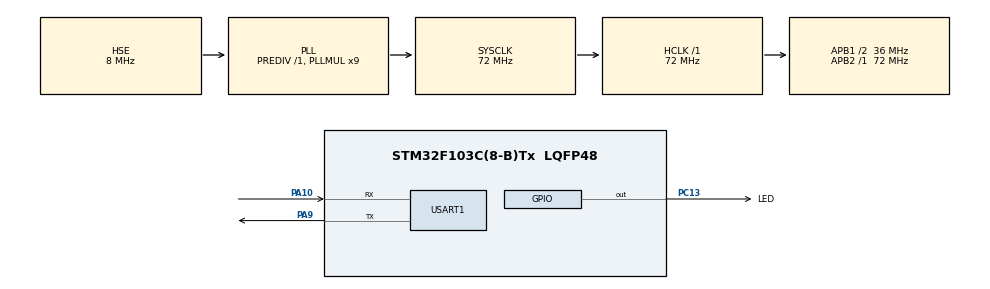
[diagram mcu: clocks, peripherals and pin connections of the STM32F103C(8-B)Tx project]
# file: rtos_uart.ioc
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FREERTOS.Tasks01=defaultTask,0,128,StartDefaultTask,Default,NULL
Mcu.Family=STM32F1
Mcu.Name=STM32F103C(8-B)Tx
Mcu.Package=LQFP48
NVIC.PriorityGroup=NVIC_PRIORITYGROUP_4
PA10.Mode=Asynchronous
PA10.Signal=USART1_RX
PA13.Mode=Serial_Wire
PA13.Signal=SYS_JTMS-SWDIO
PA14.Mode=Serial_Wire
PA14.Signal=SYS_JTCK-SWCLK
PA9.Mode=Asynchronous
PA9.Signal=USART1_TX
PC13-TAMPER-RTC.GPIO_Label=LED
PC13-TAMPER-RTC.Signal=GPIO_Output
PD0-OSC_IN.Mode=HSE-External-Oscillator
PD0-OSC_IN.Signal=RCC_OSC_IN
PD1-OSC_OUT.Mode=HSE-External-Oscillator
PD1-OSC_OUT.Signal=RCC_OSC_OUT
ProjectManager.HeapSize=0x200
ProjectManager.StackSize=0x400
ProjectManager.TargetToolchain=Makefile
RCC.AHBFreq_Value=72000000
RCC.APB1CLKDivider=RCC_HCLK_DIV2
RCC.APB1Freq_Value=36000000
RCC.APB1TimFreq_Value=72000000
RCC.APB2Freq_Value=72000000
RCC.APB2TimFreq_Value=72000000
RCC.HCLKFreq_Value=72000000
RCC.PLLMUL=RCC_PLL_MUL9
RCC.PLLSourceVirtual=RCC_PLLSOURCE_HSE
RCC.SYSCLKFreq_VALUE=72000000
RCC.SYSCLKSource=RCC_SYSCLKSOURCE_PLLCLK
RCC.USBFreq_Value=72000000
USART1.VirtualMode=VM_ASYNC
VP_FREERTOS_VS_ENABLE.Mode=Enabled
board=custom

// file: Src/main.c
/* USER CODE BEGIN Header */
/**
  ******************************************************************************
  * @file           : main.c
  * @brief          : Main program body
  ******************************************************************************
  * This notice applies to any and all portions of this file
  * that are not between comment pairs USER CODE BEGIN and
  * USER CODE END. Other portions of this file, whether
  * inserted by the user or by software development tools
  * are owned by their respective copyright owners.
  *
  * Copyright (c) 2019 STMicroelectronics International N.V.
  * All rights reserved.
  *
  * Redistribution and use in source and binary forms, with or without
  * modification, are permitted, provided that the following conditions are met:
  *
  * 1. Redistribution of source code must retain the above copyright notice,
  *    this list of conditions and the following disclaimer.
  * 2. Redistributions in binary form must reproduce the above copyright notice,
  *    this list of conditions and the following disclaimer in the documentation
  *    and/or other materials provided with the distribution.
  * 3. Neither the name of STMicroelectronics nor the names of other
  *    contributors to this software may be used to endorse or promote products
  *    derived from this software without specific written permission.
  * 4. This software, including modifications and/or derivative works of this
  *    software, must execute solely and exclusively on microcontroller or
  *    microprocessor devices manufactured by or for STMicroelectronics.
  * 5. Redistribution and use of this software other than as permitted under
  *    this license is void and will automatically terminate your rights under
  *    this license.
  *
  * THIS SOFTWARE IS PROVIDED BY STMICROELECTRONICS AND CONTRIBUTORS "AS IS"
  * AND ANY EXPRESS, IMPLIED OR STATUTORY WARRANTIES, INCLUDING, BUT NOT
  * LIMITED TO, THE IMPLIED WARRANTIES OF MERCHANTABILITY, FITNESS FOR A
  * PARTICULAR PURPOSE AND NON-INFRINGEMENT OF THIRD PARTY INTELLECTUAL PROPERTY
  * RIGHTS ARE DISCLAIMED TO THE FULLEST EXTENT PERMITTED BY LAW. IN NO EVENT
  * SHALL STMICROELECTRONICS OR CONTRIBUTORS BE LIABLE FOR ANY DIRECT, INDIRECT,
  * INCIDENTAL, SPECIAL, EXEMPLARY, OR CONSEQUENTIAL DAMAGES (INCLUDING, BUT NOT
  * LIMITED TO, PROCUREMENT OF SUBSTITUTE GOODS OR SERVICES; LOSS OF USE, DATA,
  * OR PROFITS; OR BUSINESS INTERRUPTION) HOWEVER CAUSED AND ON ANY THEORY OF
  * LIABILITY, WHETHER IN CONTRACT, STRICT LIABILITY, OR TORT (INCLUDING
  * NEGLIGENCE OR OTHERWISE) ARISING IN ANY WAY OUT OF THE USE OF THIS SOFTWARE,
  * EVEN IF ADVISED OF THE POSSIBILITY OF SUCH DAMAGE.
  *
  ******************************************************************************
  */
/* USER CODE END Header */

#include "main.h"
#include "cmsis_os.h"

UART_HandleTypeDef huart1;

osThreadId defaultTaskHandle;

void SystemClock_Config(void);
static void MX_GPIO_Init(void);
static void MX_USART1_UART_Init(void);
void StartDefaultTask(void const * argument);

/* USER CODE BEGIN 0 */
uint32_t mstrlen(const uint8_t* str, uint32_t maxsize) {
	uint32_t i = 0;
	for (i = 0; maxsize >= i && str[i] != '\0'; ++i);
	return i;
}

void LED_Task() {
	uint8_t str[]="USART Transmit \r\n";
	uint8_t len = mstrlen(str, 255);

	uint8_t counter = 0;
	while (1) {
		HAL_GPIO_TogglePin(GPIOC, GPIO_PIN_13);
		vTaskDelay(1000);

		str[len - 3] = '0' + counter++;
		HAL_UART_Transmit(&huart1, (uint8_t*)str, len, 0xFFFF);
		if (counter > 9)
			counter = 0;
	}
}
/* USER CODE END 0 */

int main(void)
{

  /* MCU Configuration--------------------------------------------------------*/

  /* Reset of all peripherals, Initializes the Flash interface and the Systick. */
  HAL_Init();

  /* Configure the system clock */
  SystemClock_Config();

  /* Initialize all configured peripherals */
  MX_GPIO_Init();
  MX_USART1_UART_Init();

  /* Create the thread(s) */
  /* definition and creation of defaultTask */
  osThreadDef(defaultTask, StartDefaultTask, osPriorityNormal, 0, 128);
  defaultTaskHandle = osThreadCreate(osThread(defaultTask), NULL);

  /* USER CODE BEGIN RTOS_THREADS */
  /* add threads, ... */
	xTaskCreate(LED_Task, "LED_Blink", configMINIMAL_STACK_SIZE, NULL, 1, NULL);
  /* USER CODE END RTOS_THREADS */

  /* Start scheduler */
  osKernelStart();
	vTaskStartScheduler();
  /* We should never get here as control is now taken by the scheduler */

  /* Infinite loop */
  while (1)
  {

  }
}

void SystemClock_Config(void)
{
  RCC_OscInitTypeDef RCC_OscInitStruct = {0};
  RCC_ClkInitTypeDef RCC_ClkInitStruct = {0};

  /**Initializes the CPU, AHB and APB busses clocks
  */
  RCC_OscInitStruct.OscillatorType = RCC_OSCILLATORTYPE_HSE;
  RCC_OscInitStruct.HSEState = RCC_HSE_ON;
  RCC_OscInitStruct.HSEPredivValue = RCC_HSE_PREDIV_DIV1;
  RCC_OscInitStruct.HSIState = RCC_HSI_ON;
  RCC_OscInitStruct.PLL.PLLState = RCC_PLL_ON;
  RCC_OscInitStruct.PLL.PLLSource = RCC_PLLSOURCE_HSE;
  RCC_OscInitStruct.PLL.PLLMUL = RCC_PLL_MUL9;
  if (HAL_RCC_OscConfig(&RCC_OscInitStruct) != HAL_OK)
  {
    Error_Handler();
  }
  /**Initializes the CPU, AHB and APB busses clocks
  */
  RCC_ClkInitStruct.ClockType = RCC_CLOCKTYPE_HCLK|RCC_CLOCKTYPE_SYSCLK
                              |RCC_CLOCKTYPE_PCLK1|RCC_CLOCKTYPE_PCLK2;
  RCC_ClkInitStruct.SYSCLKSource = RCC_SYSCLKSOURCE_PLLCLK;
  RCC_ClkInitStruct.AHBCLKDivider = RCC_SYSCLK_DIV1;
  RCC_ClkInitStruct.APB1CLKDivider = RCC_HCLK_DIV2;
  RCC_ClkInitStruct.APB2CLKDivider = RCC_HCLK_DIV1;

  if (HAL_RCC_ClockConfig(&RCC_ClkInitStruct, FLASH_LATENCY_2) != HAL_OK)
  {
    Error_Handler();
  }
}

static void MX_USART1_UART_Init(void)
{

  huart1.Instance = USART1;
  huart1.Init.BaudRate = 115200;
  huart1.Init.WordLength = UART_WORDLENGTH_8B;
  huart1.Init.StopBits = UART_STOPBITS_1;
  huart1.Init.Parity = UART_PARITY_NONE;
  huart1.Init.Mode = UART_MODE_TX_RX;
  huart1.Init.HwFlowCtl = UART_HWCONTROL_NONE;
  huart1.Init.OverSampling = UART_OVERSAMPLING_16;
  if (HAL_UART_Init(&huart1) != HAL_OK)
  {
    Error_Handler();
  }

}

static void MX_GPIO_Init(void)
{
  GPIO_InitTypeDef GPIO_InitStruct = {0};

  /* GPIO Ports Clock Enable */
  __HAL_RCC_GPIOC_CLK_ENABLE();
  __HAL_RCC_GPIOD_CLK_ENABLE();
  __HAL_RCC_GPIOA_CLK_ENABLE();

  /*Configure GPIO pin Output Level */
  HAL_GPIO_WritePin(LED_GPIO_Port, LED_Pin, GPIO_PIN_RESET);

  /*Configure GPIO pin : LED_Pin */
  GPIO_InitStruct.Pin = LED_Pin;
  GPIO_InitStruct.Mode = GPIO_MODE_OUTPUT_PP;
  GPIO_InitStruct.Pull = GPIO_NOPULL;
  GPIO_InitStruct.Speed = GPIO_SPEED_FREQ_LOW;
  HAL_GPIO_Init(LED_GPIO_Port, &GPIO_InitStruct);

}

void StartDefaultTask(void const * argument)
{

  for(;;)
  {
    osDelay(1);
  }
}

void Error_Handler(void)
{
}

/************************ (C) COPYRIGHT STMicroelectronics *****END OF FILE****/
